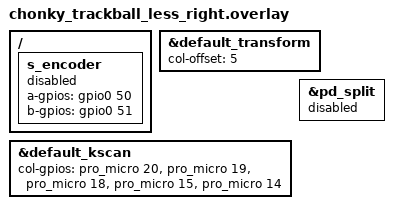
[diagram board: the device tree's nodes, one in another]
/*
 * Copyright (c) 2020 Pete Johanson
 *
 * SPDX-License-Identifier: MIT
 */

#include "chonky_trackball_less.dtsi"

&default_transform {
    col-offset = <5>;
};

&default_kscan {
    col-gpios
        = <&pro_micro 20 (GPIO_ACTIVE_HIGH | GPIO_PULL_DOWN)>
        , <&pro_micro 19 (GPIO_ACTIVE_HIGH | GPIO_PULL_DOWN)>
        , <&pro_micro 18 (GPIO_ACTIVE_HIGH | GPIO_PULL_DOWN)>
        , <&pro_micro 15 (GPIO_ACTIVE_HIGH | GPIO_PULL_DOWN)>
        , <&pro_micro 14 (GPIO_ACTIVE_HIGH | GPIO_PULL_DOWN)>
        ;
};

&pd_split {
    status = "disabled";
};

/{
	s_encoder: s_encoder {
		status = "disabled";
		a-gpios = <&gpio0 50  (GPIO_ACTIVE_HIGH | GPIO_PULL_UP)>;
		b-gpios = <&gpio0 51  (GPIO_ACTIVE_HIGH | GPIO_PULL_UP)>;
	};
};
